AUTOSAR XML (schema 4-2-1)
package /RootP_BSWC_NvDM
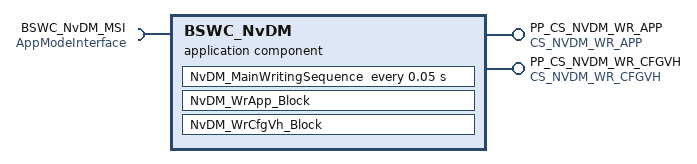
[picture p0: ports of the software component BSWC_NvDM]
  application sw component type BSWC_NvDM
    provide port PP_CS_NVDM_WR_APP: server-com-spec{operation=NvDM_WrApp_Block, queue-length=1}, provided-interface=CS_NVDM_WR_APP
    provide port PP_CS_NVDM_WR_CFGVH: server-com-spec{operation=NvDM_WrCfgVh_Block, queue-length=1}, provided-interface=CS_NVDM_WR_CFGVH
    require port BSWC_NvDM_MSI: required-interface=AppModeInterface
    behavior IB_BSWC_NvDM: data-type-mapping=ApplicationModeMapping, handle-termination-and-restart=NO-SUPPORT
      operation invoked event CS_NVDM_WR_APP_NvDM_WrApp_Block_OIE: start-on-event=NvDM_WrApp_Block, operation=PP_CS_NVDM_WR_APP.NvDM_WrApp_Block
      operation invoked event CS_NVDM_WR_CFGVH_NvDM_WrCfgVh_Block_OIE: start-on-event=NvDM_WrCfgVh_Block, operation=PP_CS_NVDM_WR_CFGVH.NvDM_WrCfgVh_Block
      timing event NvDM_MainWritingSequence_Cyclic: start-on-event=NvDM_MainWritingSequence, period=0.05
        disabled-mode:
          BSWC_NvDM_MSI.AppMode.APP_WAKEUP
          BSWC_NvDM_MSI.AppMode.APP_OFF
          BSWC_NvDM_MSI.AppMode.APP_SYNC_INIT
          BSWC_NvDM_MSI.AppMode.APP_CONFIG
      runnable NvDM_MainWritingSequence
      runnable NvDM_WrApp_Block
      runnable NvDM_WrCfgVh_Block
package /RootP_Implementatation
  swc implementation Implementatation_BSWC_NvDM: programming-language=C, sw-version=1.0.0, vendor-id=1, behavior=IB_BSWC_NvDM
    code-descriptors:
      code SRC: artifact-descriptors=autosar-engineering-object={short-label=EngObject, category=SWSRC}
    resource consumption Resources
